VERSION ""

NS_ :

BS_:
BU_: Dashboard PEI TelemNode
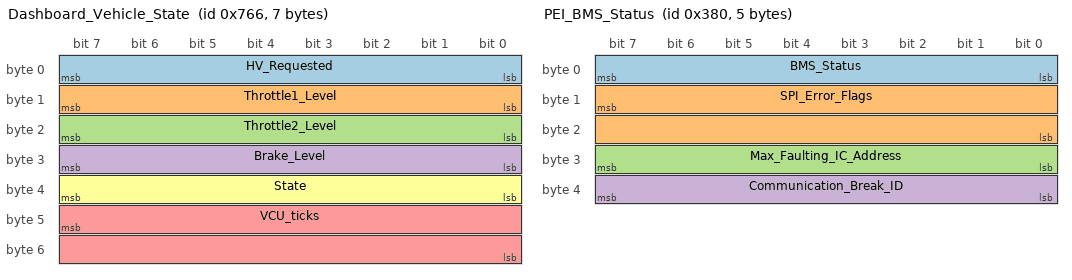
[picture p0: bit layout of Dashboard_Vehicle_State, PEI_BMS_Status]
BO_ 1894 Dashboard_Vehicle_State: 7 Dashboard
   SG_ HV_Requested : 7|8@0+ (1,0) [0|1] "" Vector__XXX
   SG_ Throttle1_Level : 15|8@0+ (1,0) [0|100] "%" Vector__XXX
   SG_ Throttle2_Level : 23|8@0+ (1,0) [0|100] "%" Vector__XXX
   SG_ Brake_Level : 31|8@0+ (1,0) [0|100] "%" Vector__XXX
   SG_ VCU_ticks : 47|16@0+ (1,0) [0|65535] "ms" Vector__XXX
   SG_ State : 39|8@0+ (1,0) [0|255] "" Vector__XXX

BO_ 896 PEI_BMS_Status: 5 PEI
   SG_ BMS_Status : 7|8@0+ (1,0) [0|255] "" Vector__XXX
   SG_ SPI_Error_Flags : 15|16@0+ (1,0) [0|65535] "" Vector__XXX
   SG_ Max_Faulting_IC_Address : 31|8@0+ (1,0) [0|9] "" Vector__XXX
   SG_ Communication_Break_ID : 39|8@0- (1,0) [-1|9] "" Vector__XXX

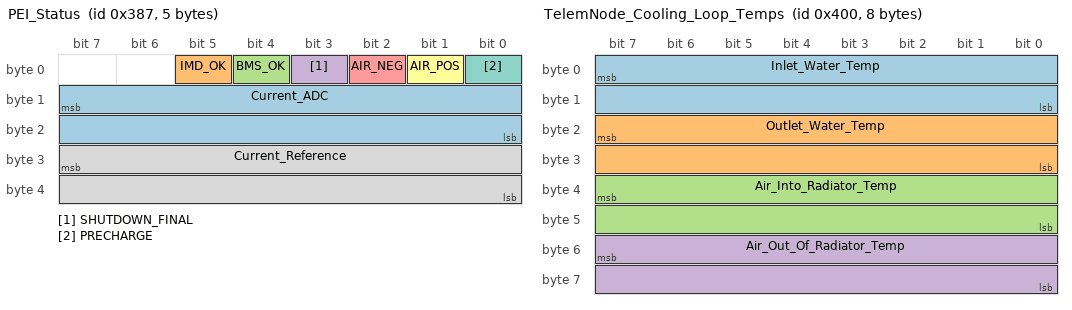
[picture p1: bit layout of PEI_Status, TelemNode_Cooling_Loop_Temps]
BO_ 903 PEI_Status: 5 PEI
   SG_ Current_ADC : 15|16@0+ (1,0) [0|65535] "A" Vector__XXX
   SG_ IMD_OK : 5|1@0+ (1,0) [0|1] "" Vector__XXX
   SG_ BMS_OK : 4|1@0+ (1,0) [0|1] "" Vector__XXX
   SG_ SHUTDOWN_FINAL : 3|1@0+ (1,0) [0|1] "" Vector__XXX
   SG_ AIR_NEG : 2|1@0+ (1,0) [0|1] "" Vector__XXX
   SG_ AIR_POS : 1|1@0+ (1,0) [0|1] "" Vector__XXX
   SG_ PRECHARGE : 0|1@0+ (1,0) [0|1] "" Vector__XXX
   SG_ Current_Reference : 31|16@0+ (1,0) [0|65535] "" Vector__XXX

BO_ 1024 TelemNode_Cooling_Loop_Temps: 8 TelemNode
   SG_ Inlet_Water_Temp : 7|16@0- (0.1,0) [-3276.8|3276.7] "C" Vector__XXX
   SG_ Outlet_Water_Temp : 23|16@0- (0.1,0) [-3276.8|3276.7] "C" Vector__XXX
   SG_ Air_Into_Radiator_Temp : 39|16@0- (0.1,0) [-3276.8|3276.7] "C" Vector__XXX
   SG_ Air_Out_Of_Radiator_Temp : 55|16@0- (0.1,0) [-3276.8|3276.7] "" Vector__XXX

BO_ 1026 TelemNode_Cool_Loop_Pressures: 4 TelemNode
   SG_ Inlet_Water_Pressure : 7|16@0+ (0.01,0) [0|1] "PSI" Vector__XXX
   SG_ Outlet_Water_Pressure : 23|16@0+ (0.01,0) [0|1] "PSI" Vector__XXX

BO_ 1025 TelemNode_Wheel_Speed_Rear: 4 TelemNode
   SG_ Wheel_Speed_Rear_Right : 7|16@0+ (1,0) [0|65535] "CPS/RPM" Vector__XXX
   SG_ Wheel_Speed_Rear_Left : 23|16@0+ (1,0) [0|65535] "CPS/RPM" Vector__XXX

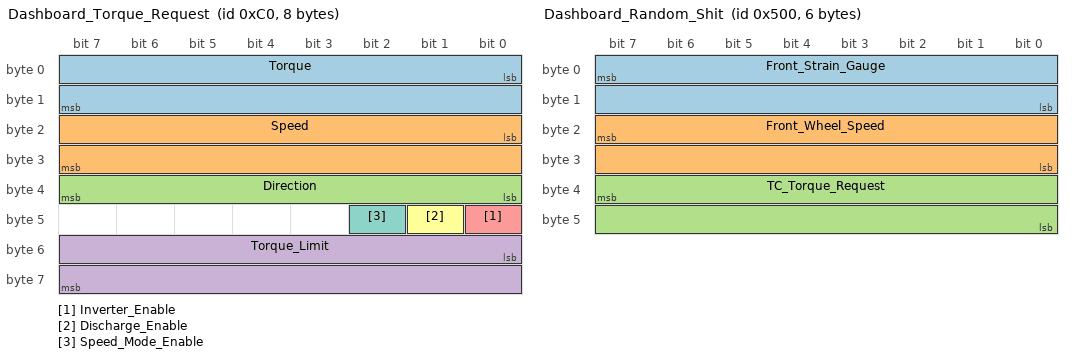
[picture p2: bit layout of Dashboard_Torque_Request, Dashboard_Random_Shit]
BO_ 192 Dashboard_Torque_Request: 8 Dashboard
   SG_ Torque : 0|16@1+ (0.1,0) [0|6553.5] "Nm" Vector__XXX
   SG_ Speed : 16|16@1+ (1,0) [0|65535] "RPM" Vector__XXX
   SG_ Direction : 32|8@1+ (1,0) [0|1] "" Vector__XXX
   SG_ Torque_Limit : 48|16@1+ (0.1,0) [0|6553.5] "Nm" Vector__XXX
   SG_ Inverter_Enable : 40|1@1+ (1,0) [0|1] "" Vector__XXX
   SG_ Discharge_Enable : 41|1@1+ (1,0) [0|1] "" Vector__XXX
   SG_ Speed_Mode_Enable : 42|1@1+ (1,0) [0|1] "" Vector__XXX

BO_ 1280 Dashboard_Random_Shit: 6 Dashboard
   SG_ Front_Strain_Gauge : 7|16@0+ (1,0) [0|65535] "" Vector__XXX
   SG_ Front_Wheel_Speed : 23|16@0+ (1,0) [0|65535] "RPM" Vector__XXX
   SG_ TC_Torque_Request : 39|16@0+ (0.1,0) [0|6553.5] "Nm" Vector__XXX

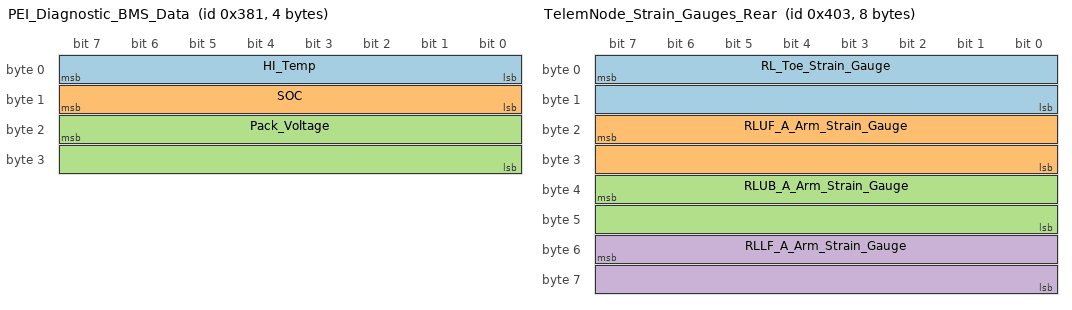
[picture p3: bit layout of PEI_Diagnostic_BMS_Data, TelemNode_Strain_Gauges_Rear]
BO_ 897 PEI_Diagnostic_BMS_Data: 4 PEI
   SG_ HI_Temp : 7|8@0+ (1,0) [0|255] "C" Vector__XXX
   SG_ SOC : 15|8@0+ (1,0) [0|100] "%" Vector__XXX
   SG_ Pack_Voltage : 23|16@0- (1,0) [-32768|32767] "V" Vector__XXX

BO_ 1027 TelemNode_Strain_Gauges_Rear: 8 TelemNode
   SG_ RL_Toe_Strain_Gauge : 7|16@0+ (1,0) [0|65535] "" Vector__XXX
   SG_ RLUF_A_Arm_Strain_Gauge : 23|16@0+ (1,0) [0|65535] "" Vector__XXX
   SG_ RLUB_A_Arm_Strain_Gauge : 39|16@0+ (1,0) [0|65535] "" Vector__XXX
   SG_ RLLF_A_Arm_Strain_Gauge : 55|16@0+ (1,0) [0|65535] "" Vector__XXX

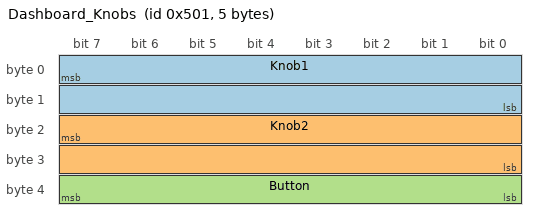
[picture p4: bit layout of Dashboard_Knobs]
BO_ 1281 Dashboard_Knobs: 5 Dashboard
   SG_ Knob1 : 7|16@0+ (1,0) [0|4095] "" Vector__XXX
   SG_ Knob2 : 23|16@0+ (1,0) [0|4095] "" Vector__XXX
   SG_ Button : 39|8@0+ (1,0) [0|1] "" Vector__XXX

BA_DEF_ BO_ "GenMsgBackgroundColor" STRING ;
BA_DEF_ BO_ "GenMsgForegroundColor" STRING ;
BA_DEF_ BO_ "filterlabeling" INT 0 0;
BA_DEF_ "BusType" STRING ;
BA_DEF_ BO_ "GenMsgBackgroundColor" STRING ;
BA_DEF_ BO_ "GenMsgForegroundColor" STRING ;
BA_DEF_ BO_ "filterlabeling" INT 0 0;
BA_DEF_ BO_ "filterlabeling" INT 0 0;
BA_DEF_DEF_ "GenMsgBackgroundColor" "#ffffff";
BA_DEF_DEF_ "GenMsgForegroundColor" "#000000";
BA_DEF_DEF_ "filterlabeling" 1;
BA_DEF_DEF_ "BusType" "CAN";
BA_DEF_DEF_ "filterlabeling" 1;
VAL_ 1894 State 0 "LV" 1 "PRECHARGE" 2 "HV_ENABLED" 3 "DRIVE" 5 "STARTUP" 129 "DRV_FRM_LV" 130 "PRE_TM_OUT" 131 "BR_NOT_PRS" 132 "HV_OFF_DRV" 133 "SNSR_DSCRP" 135 "SHTDWN_OPN" 137 "HARD_BSPD" 138 "MC_FAULT" 134 "BSPD_TRIPD" 136 "UNCALIBRTD";
VAL_ 896 BMS_Status 0 "NO_ERROR" 1 "CHARGE_MODE" 2 "BMS_TEMP_OVER" 4 "BMS_TEMP_UNDER" 8 "OVERVOLT" 16 "UNDERVOLT" 32 "OPEN_WIRE" 64 "MISMATCH" 128 "SPI_FAULT";
